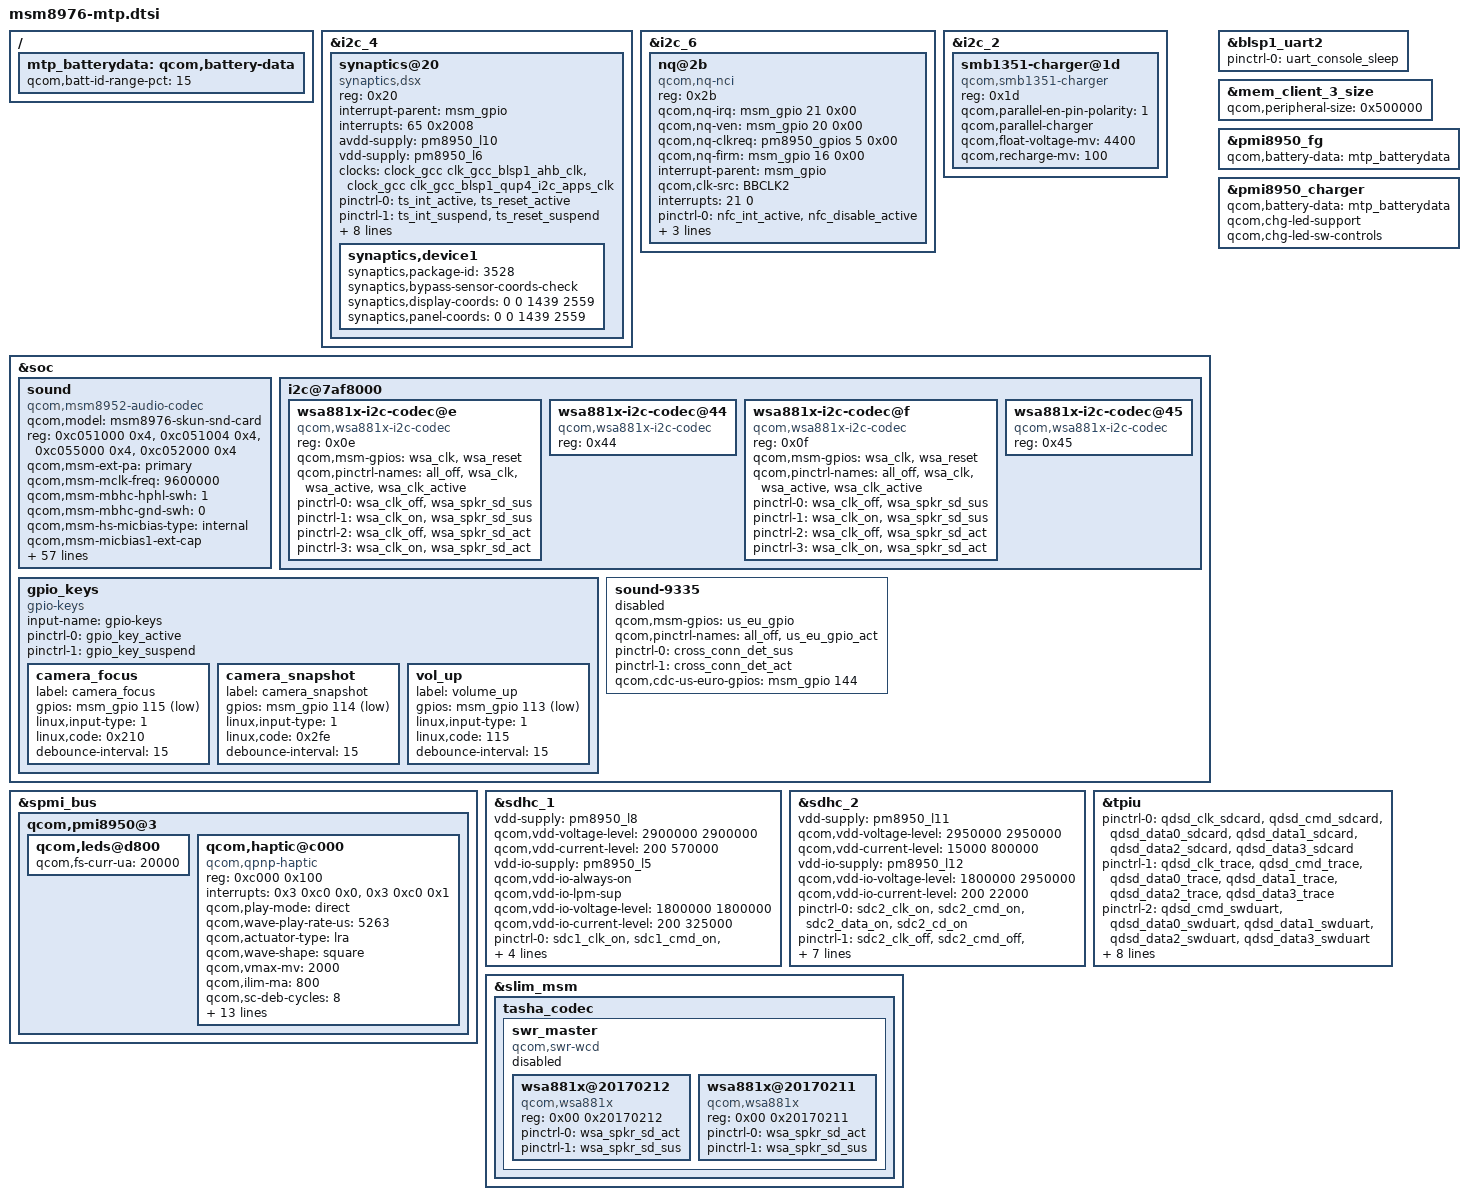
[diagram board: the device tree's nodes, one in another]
/*
 * Copyright (c) 2015, The Linux Foundation. All rights reserved.
 *
 * This program is free software; you can redistribute it and/or modify
 * it under the terms of the GNU General Public License version 2 and
 * only version 2 as published by the Free Software Foundation.
 *
 * This program is distributed in the hope that it will be useful,
 * but WITHOUT ANY WARRANTY; without even the implied warranty of
 * MERCHANTABILITY or FITNESS FOR A PARTICULAR PURPOSE.  See the
 * GNU General Public License for more details.
 */

#include "msm8976-pinctrl.dtsi"
#include "msm8976-camera-sensor-mtp.dtsi"
#include "msm8976-mdss-mtp.dtsi"
#include "msm8976-wsa881x.dtsi"

&i2c_4 { /* BLSP1 QUP4 */
	synaptics@20 {
		compatible = "synaptics,dsx";
		reg = <0x20>;
		interrupt-parent = <&msm_gpio>;
		interrupts = <65 0x2008>;
		avdd-supply = <&pm8950_l10>;
		vdd-supply = <&pm8950_l6>;
		clock-names = "iface_clk", "core_clk";
		clocks = <&clock_gcc clk_gcc_blsp1_ahb_clk>,
			<&clock_gcc clk_gcc_blsp1_qup4_i2c_apps_clk>;
		/* pins used by touchscreen */
		pinctrl-names = "pmx_ts_active","pmx_ts_suspend","pmx_ts_release";
		pinctrl-0 = <&ts_int_active &ts_reset_active>;
		pinctrl-1 = <&ts_int_suspend &ts_reset_suspend>;
		pinctrl-2 = <&ts_release>;
		synaptics,irq-gpio = <&msm_gpio 65 0x2008>;
		synaptics,reset-gpio = <&msm_gpio 64 0x0>;
		synaptics,i2c-pull-up;
		synaptics,power-down;
		synaptics,disable-gpios;
		synaptics,detect-device;
		synaptics,bypass-packrat-id-check;
		synaptics,device1 {
			synaptics,package-id = <3528>;
			synaptics,bypass-sensor-coords-check;
			synaptics,display-coords = <0 0 1439 2559>;
			synaptics,panel-coords = <0 0 1439 2559>;
		};
	};
};

&i2c_6 { /* BLSP2 QUP2 */
	nq@2b {
		compatible = "qcom,nq-nci";
		reg = <0x2b>;
		qcom,nq-irq = <&msm_gpio 21 0x00>;
		qcom,nq-ven = <&msm_gpio 20 0x00>;
		qcom,nq-clkreq = <&pm8950_gpios 5 0x00>;
		qcom,nq-firm = <&msm_gpio 16 0x00>;
		interrupt-parent = <&msm_gpio>;
		qcom,clk-src = "BBCLK2";
		interrupts = <21 0>;
		interrupt-names = "nfc_irq";
		pinctrl-names = "nfc_active", "nfc_suspend";
		pinctrl-0 = <&nfc_int_active &nfc_disable_active>;
		pinctrl-1 = <&nfc_int_suspend &nfc_disable_suspend>;
		clocks = <&clock_gcc clk_bb_clk2_pin>;
		clock-names = "ref_clk";
	};
};

&i2c_2 {
	/* Parallel-charger configuration */
	smb1351-charger@1d {
		compatible = "qcom,smb1351-charger";
		reg = <0x1d>;
		qcom,parallel-en-pin-polarity = <1>;
		qcom,parallel-charger;
		qcom,float-voltage-mv = <4400>;
		qcom,recharge-mv = <100>;
	};
};

&soc {

	sound {
		compatible = "qcom,msm8952-audio-codec";
		qcom,model = "msm8976-skun-snd-card";
		reg = <0xc051000 0x4>,
		      <0xc051004 0x4>,
		      <0xc055000 0x4>,
		      <0xc052000 0x4>;
		reg-names = "csr_gp_io_mux_mic_ctl",
			    "csr_gp_io_mux_spkr_ctl",
			    "csr_gp_io_lpaif_pri_pcm_pri_mode_muxsel",
			    "csr_gp_io_mux_quin_ctl";

		qcom,msm-ext-pa = "primary";
		qcom,msm-mclk-freq = <9600000>;
		qcom,msm-mbhc-hphl-swh = <1>;
		qcom,msm-mbhc-gnd-swh = <0>;
		qcom,msm-hs-micbias-type = "internal";
		qcom,msm-micbias1-ext-cap;
		qcom,msm-micbias2-ext-cap;
		qcom,audio-routing =
			"RX_BIAS", "MCLK",
			"SPK_RX_BIAS", "MCLK",
			"INT_LDO_H", "MCLK",
			"MIC BIAS External", "Handset Mic",
			"MIC BIAS Internal2", "Headset Mic",
			"MIC BIAS External", "Secondary Mic",
			"AMIC1", "MIC BIAS External",
			"AMIC2", "MIC BIAS Internal2",
			"AMIC3", "MIC BIAS External",
			"WSA_SPK OUT", "VDD_WSA_SWITCH",
			"SpkrMono WSA_IN", "WSA_SPK OUT";
		qcom,msm-gpios =
			"pri_i2s";
		qcom,pinctrl-names =
			"all_off",
			"pri_i2s_act";
		pinctrl-names =
			"all_off",
			"pri_i2s_act";
		pinctrl-0 = <&cdc_pdm_lines_sus &cdc_pdm_lines_2_sus>;
		pinctrl-1 = <&cdc_pdm_lines_act &cdc_pdm_lines_2_act>;
		asoc-platform = <&pcm0>, <&pcm1>, <&pcm2>, <&voip>, <&voice>,
				<&loopback>, <&compress>, <&hostless>,
				<&afe>, <&lsm>, <&routing>, <&lpa>,
				<&voice_svc>;
		asoc-platform-names = "msm-pcm-dsp.0", "msm-pcm-dsp.1",
				"msm-pcm-dsp.2", "msm-voip-dsp",
				"msm-pcm-voice", "msm-pcm-loopback",
				"msm-compress-dsp", "msm-pcm-hostless",
				"msm-pcm-afe", "msm-lsm-client",
				"msm-pcm-routing", "msm-pcm-lpa",
				"msm-voice-svc";
		asoc-cpu = <&dai_pri_auxpcm>, <&dai_hdmi>,
				<&dai_mi2s0>, <&dai_mi2s1>, <&dai_mi2s2>,
				<&dai_mi2s3>, <&dai_mi2s5>, <&dai_mi2s5>,
				<&sb_0_rx>, <&sb_0_tx>, <&sb_1_rx>, <&sb_1_tx>,
				<&sb_3_rx>, <&sb_3_tx>, <&sb_4_rx>, <&sb_4_tx>,
				<&bt_sco_rx>, <&bt_sco_tx>, <&int_fm_rx>,
				<&int_fm_tx>, <&afe_pcm_rx>, <&afe_pcm_tx>,
				<&afe_proxy_rx>, <&afe_proxy_tx>,
				<&incall_record_rx>, <&incall_record_tx>,
				<&incall_music_rx>, <&incall_music_2_rx>;
		asoc-cpu-names = "msm-dai-q6-auxpcm.1", "msm-dai-q6-hdmi.8",
				"msm-dai-q6-mi2s.0", "msm-dai-q6-mi2s.1",
				"msm-dai-q6-mi2s.2", "msm-dai-q6-mi2s.3",
				"msm-dai-q6-mi2s.5", "msm-dai-q6-mi2s.6",
				"msm-dai-q6-dev.16384", "msm-dai-q6-dev.16385",
				"msm-dai-q6-dev.16386", "msm-dai-q6-dev.16387",
				"msm-dai-q6-dev.16390", "msm-dai-q6-dev.16391",
				"msm-dai-q6-dev.16392", "msm-dai-q6-dev.16393",
				"msm-dai-q6-dev.12288", "msm-dai-q6-dev.12289",
				"msm-dai-q6-dev.12292", "msm-dai-q6-dev.12293",
				"msm-dai-q6-dev.224", "msm-dai-q6-dev.225",
				"msm-dai-q6-dev.241", "msm-dai-q6-dev.240",
				"msm-dai-q6-dev.32771", "msm-dai-q6-dev.32772",
				"msm-dai-q6-dev.32773", "msm-dai-q6-dev.32770";
		asoc-codec = <&stub_codec>, <&pm8950_cajon_dig>;
		asoc-codec-names = "msm-stub-codec.1", "cajon_codec";
		asoc-wsa-codec-names = "wsa881x-i2c-codec.8-000f";
		asoc-wsa-codec-prefixes = "SpkrMono";

		msm-vdd-wsa-switch-supply = <&pm8950_l13>;
		qcom,msm-vdd-wsa-switch-voltage = <3075000>;
		qcom,msm-vdd-wsa-switch-current = <5000>;
	};

	i2c@7af8000 {
		wsa881x-i2c-codec@e {
			compatible = "qcom,wsa881x-i2c-codec";
			reg = <0x0e>;
			qcom,msm-gpios = "wsa_clk",
					"wsa_reset";
			qcom,pinctrl-names = "all_off",
					"wsa_clk",
					"wsa_active",
					"wsa_clk_active";
			pinctrl-names = "all_off",
					"wsa_clk",
					"wsa_active",
					"wsa_clk_active";
			pinctrl-0 = <&wsa_clk_off &wsa_spkr_sd_sus>;
			pinctrl-1 = <&wsa_clk_on &wsa_spkr_sd_sus>;
			pinctrl-2 = <&wsa_clk_off &wsa_spkr_sd_act>;
			pinctrl-3 = <&wsa_clk_on &wsa_spkr_sd_act>;
		};

		wsa881x-i2c-codec@44 {
			compatible = "qcom,wsa881x-i2c-codec";
			reg = <0x44>;
		};

		wsa881x-i2c-codec@f {
			compatible = "qcom,wsa881x-i2c-codec";
			reg = <0x0f>;
			qcom,msm-gpios = "wsa_clk",
					"wsa_reset";
			qcom,pinctrl-names = "all_off",
					"wsa_clk",
					"wsa_active",
					"wsa_clk_active";
			pinctrl-names = "all_off",
					"wsa_clk",
					"wsa_active",
					"wsa_clk_active";
			pinctrl-0 = <&wsa_clk_off &wsa_spkr_sd_sus>;
			pinctrl-1 = <&wsa_clk_on &wsa_spkr_sd_sus>;
			pinctrl-2 = <&wsa_clk_off &wsa_spkr_sd_act>;
			pinctrl-3 = <&wsa_clk_on &wsa_spkr_sd_act>;
		};

		wsa881x-i2c-codec@45 {
			compatible = "qcom,wsa881x-i2c-codec";
			reg = <0x45>;
		};
	};

	gpio_keys {
		compatible = "gpio-keys";
		input-name = "gpio-keys";
		pinctrl-names = "tlmm_gpio_key_active","tlmm_gpio_key_suspend";
		pinctrl-0 = <&gpio_key_active>;
		pinctrl-1 = <&gpio_key_suspend>;

		camera_focus {
			label = "camera_focus";
			gpios = <&msm_gpio 115 0x1>;
			linux,input-type = <1>;
			linux,code = <0x210>;
			debounce-interval = <15>;
		};

		camera_snapshot {
			label = "camera_snapshot";
			gpios = <&msm_gpio 114 0x1>;
			linux,input-type = <1>;
			linux,code = <0x2fe>;
			debounce-interval = <15>;
		};

		vol_up {
			label = "volume_up";
			gpios = <&msm_gpio 113 0x1>;
			linux,input-type = <1>;
			linux,code = <115>;
			debounce-interval = <15>;
		};
	};

	sound-9335 {
		status = "disabled";
		qcom,msm-gpios =
			"us_eu_gpio";
		qcom,pinctrl-names =
			"all_off",
			"us_eu_gpio_act";
		pinctrl-names =
			"all_off",
			"us_eu_gpio_act";
		pinctrl-0 = <&cross_conn_det_sus>;
		pinctrl-1 = <&cross_conn_det_act>;
		qcom,cdc-us-euro-gpios = <&msm_gpio 144 0>;
	};
};

&blsp1_uart2 {
	status = "ok";
	pinctrl-names = "default";
	pinctrl-0 = <&uart_console_sleep>;
};

&mem_client_3_size {
	qcom,peripheral-size = <0x500000>;
};

&spmi_bus {
	qcom,pmi8950@3 {
		qcom,leds@d800 {
			qcom,fs-curr-ua = <20000>;
		};

		qcom,haptic@c000 {
			compatible = "qcom,qpnp-haptic";
			reg = <0xc000 0x100>;
			interrupts = <0x3 0xc0 0x0>,
				<0x3 0xc0 0x1>;
			interrupt-names = "sc-irq", "play-irq";
			qcom,play-mode = "direct";
			qcom,wave-play-rate-us = <5263>;
			qcom,actuator-type = "lra";
			qcom,wave-shape = "square";
			qcom,vmax-mv = <2000>;
			qcom,ilim-ma = <800>;
			qcom,sc-deb-cycles = <8>;
			qcom,int-pwm-freq-khz = <505>;
			qcom,en-brake;
			qcom,brake-pattern = [03 03 00 00];
			qcom,use-play-irq;
			qcom,use-sc-irq;
			qcom,wave-samples = [3e 3e 3e 3e 3e 3e 3e 3e];
			qcom,wave-rep-cnt = <1>;
			qcom,wave-samp-rep-cnt = <1>;
			qcom,lra-auto-res-mode="qwd";
			qcom,lra-high-z="opt1";
			qcom,lra-res-cal-period = <0>;
			qcom,correct-lra-drive-freq;
			qcom,misc-trim-error-rc19p2-clk-reg-present;
		};
	};
};

&sdhc_1 {
	vdd-supply = <&pm8950_l8>;
	qcom,vdd-voltage-level = <2900000 2900000>;
	qcom,vdd-current-level = <200 570000>;

	vdd-io-supply = <&pm8950_l5>;
	qcom,vdd-io-always-on;
	qcom,vdd-io-lpm-sup;
	qcom,vdd-io-voltage-level = <1800000 1800000>;
	qcom,vdd-io-current-level = <200 325000>;

	pinctrl-names = "active", "sleep";
	pinctrl-0 = <&sdc1_clk_on &sdc1_cmd_on &sdc1_data_on &sdc1_rclk_on>;
	pinctrl-1 = <&sdc1_clk_off &sdc1_cmd_off &sdc1_data_off &sdc1_rclk_off>;

	qcom,nonremovable;

	status = "ok";
};

&sdhc_2 {
	vdd-supply = <&pm8950_l11>;
	qcom,vdd-voltage-level = <2950000 2950000>;
	qcom,vdd-current-level = <15000 800000>;

	vdd-io-supply = <&pm8950_l12>;
	qcom,vdd-io-voltage-level = <1800000 2950000>;
	qcom,vdd-io-current-level = <200 22000>;

	pinctrl-names = "active", "sleep";
	pinctrl-0 = <&sdc2_clk_on &sdc2_cmd_on &sdc2_data_on &sdc2_cd_on>;
	pinctrl-1 = <&sdc2_clk_off &sdc2_cmd_off &sdc2_data_off &sdc2_cd_off>;

	#address-cells = <0>;
	interrupt-parent = <&sdhc_2>;
	interrupts = <0 1 2>;
	#interrupt-cells = <1>;
	interrupt-map-mask = <0xffffffff>;
	interrupt-map = <0 &intc 0 125 0
			1 &intc 0 221 0
			2 &msm_gpio 100 0>;
	interrupt-names = "hc_irq", "pwr_irq", "status_irq";
	cd-gpios = <&msm_gpio 100 0x1>;

	status = "ok";
};

/{
	mtp_batterydata: qcom,battery-data {
		qcom,batt-id-range-pct = <15>;
		#include "batterydata-itech-3000mah-4200mv.dtsi"
		#include "batterydata-itech-3000mah.dtsi"
	};
};

&pmi8950_fg {
	qcom,battery-data = <&mtp_batterydata>;
};

&pmi8950_charger {
	qcom,battery-data = <&mtp_batterydata>;
	qcom,chg-led-support;
	qcom,chg-led-sw-controls;
};

/* CoreSight */
&tpiu {
	pinctrl-names = "sdcard", "trace", "swduart",
			"swdtrc", "jtag", "spmi";
	/* NIDnT */
	pinctrl-0 = <&qdsd_clk_sdcard &qdsd_cmd_sdcard
		     &qdsd_data0_sdcard &qdsd_data1_sdcard
		     &qdsd_data2_sdcard &qdsd_data3_sdcard>;
	pinctrl-1 = <&qdsd_clk_trace &qdsd_cmd_trace
		     &qdsd_data0_trace &qdsd_data1_trace
		     &qdsd_data2_trace &qdsd_data3_trace>;
	pinctrl-2 = <&qdsd_cmd_swduart &qdsd_data0_swduart
		     &qdsd_data1_swduart &qdsd_data2_swduart
		     &qdsd_data3_swduart>;
	pinctrl-3 = <&qdsd_clk_swdtrc &qdsd_cmd_swdtrc
		     &qdsd_data0_swdtrc &qdsd_data1_swdtrc
		     &qdsd_data2_swdtrc &qdsd_data3_swdtrc>;
	pinctrl-4 = <&qdsd_cmd_jtag &qdsd_data0_jtag
		     &qdsd_data1_jtag &qdsd_data2_jtag
		     &qdsd_data3_jtag>;
	pinctrl-5 = <&qdsd_clk_spmi &qdsd_cmd_spmi
		     &qdsd_data0_spmi &qdsd_data3_spmi>;
};

&slim_msm {
	tasha_codec {
		swr_master {
			compatible = "qcom,swr-wcd";
			#address-cells = <2>;
			#size-cells = <0>;
			status = "disabled";
			wsa881x@20170212 {
				compatible = "qcom,wsa881x";
				reg = <0x00 0x20170212>;
				pinctrl-names = "wsa_spkr_sd_act",
						"wsa_spkr_sd_sus";
				pinctrl-0 = <&wsa_spkr_sd_act>;
				pinctrl-1 = <&wsa_spkr_sd_sus>;
			};

			wsa881x@20170211 {
				compatible = "qcom,wsa881x";
				reg = <0x00 0x20170211>;
				pinctrl-names = "wsa_spkr_sd_act",
						"wsa_spkr_sd_sus";
				pinctrl-0 = <&wsa_spkr_sd_act>;
				pinctrl-1 = <&wsa_spkr_sd_sus>;
			};
		};
	};
};
/*
&pm8950_cajon_dig {
	status = "disabled";
};

&pm8950_cajon_analog {
	status = "disabled";
};*/
